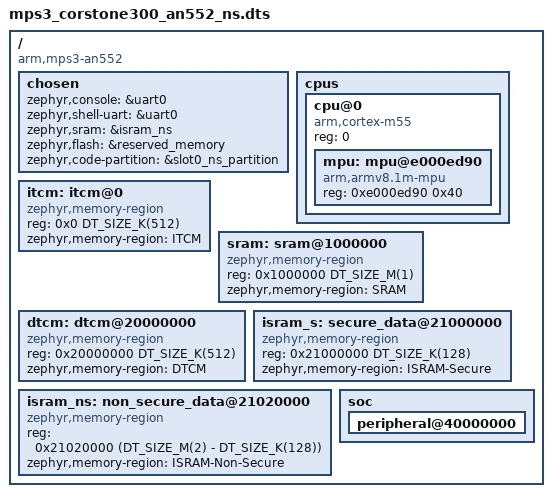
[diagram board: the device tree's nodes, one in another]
/*
 * Copyright 2024-2025 Arm Limited and/or its affiliates <open-source-office@arm.com>
 *
 * SPDX-License-Identifier: Apache-2.0
 */

/dts-v1/;

#include <arm/armv8.1-m.dtsi>
#include <zephyr/dt-bindings/i2c/i2c.h>
#include <zephyr/dt-bindings/input/input-event-codes.h>
#include <mem.h>

#include "mps3_common_ns.dtsi"

/ {
	compatible = "arm,mps3-an552";
	#address-cells = <1>;
	#size-cells = <1>;

	chosen {
		zephyr,console = &uart0;
		zephyr,shell-uart = &uart0;
		zephyr,sram = &isram_ns;
		zephyr,flash = &reserved_memory;
		zephyr,code-partition = &slot0_ns_partition;
	};

	cpus {
		#address-cells = <1>;
		#size-cells = <0>;

		cpu@0 {
			device_type = "cpu";
			compatible = "arm,cortex-m55";
			reg = <0>;
			#address-cells = <1>;
			#size-cells = <1>;

			mpu: mpu@e000ed90 {
				compatible = "arm,armv8.1m-mpu";
				reg = <0xe000ed90 0x40>;
			};
		};
	};

	/* We utilize the secure addresses, if you subtract 0x10000000
	 * you'll get the non-secure alias
	 */
	itcm: itcm@0 {
		compatible = "zephyr,memory-region";
		reg = <0x0 DT_SIZE_K(512)>;
		zephyr,memory-region = "ITCM";
	};

	sram: sram@1000000 {
		compatible = "zephyr,memory-region", "mmio-sram";
		reg = <0x1000000 DT_SIZE_M(1)>;
		zephyr,memory-region = "SRAM";
	};

	dtcm: dtcm@20000000 {
		compatible = "zephyr,memory-region";
		reg = <0x20000000 DT_SIZE_K(512)>;
		zephyr,memory-region = "DTCM";
	};

	/* The ISRAM blocks are used for both S and NS data. The S reserves 128k
	 * bytes and the remaining can be used by the NS firmware.
	 */
	isram_s: secure_data@21000000 {
		compatible = "zephyr,memory-region", "mmio-sram";
		reg = <0x21000000 DT_SIZE_K(128)>;
		zephyr,memory-region = "ISRAM-Secure";
	};

	isram_ns: non_secure_data@21020000 {
		compatible = "zephyr,memory-region", "mmio-sram";
		reg = <0x21020000 (DT_SIZE_M(2) - DT_SIZE_K(128))>;
		zephyr,memory-region = "ISRAM-Non-Secure";
	};

	soc {
		peripheral@40000000 {
			#address-cells = <1>;
			#size-cells = <1>;
			ranges = <0x0 0x40000000 0x10000000>;

			#include "mps3_common_soc_peripheral.dtsi"
		};
	};
};
#include "mps3_common.dtsi"
